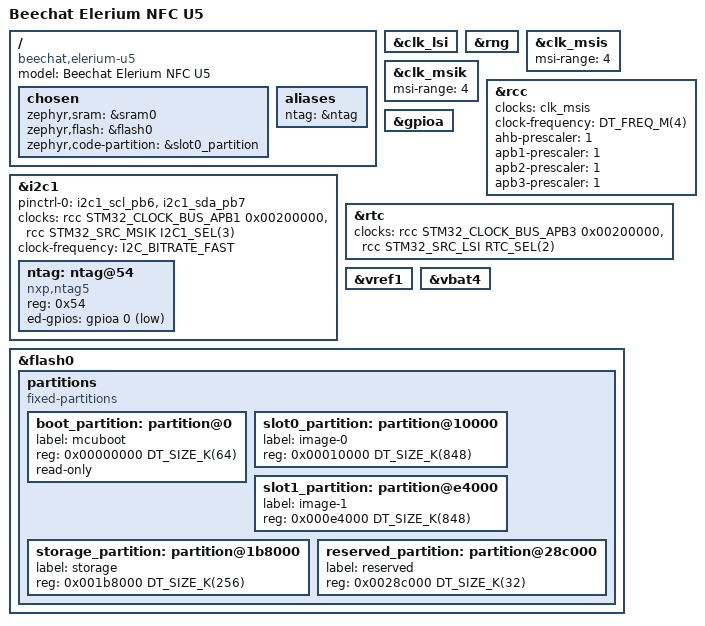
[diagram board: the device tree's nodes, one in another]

/dts-v1/;

#include <st/u5/stm32u585xi.dtsi>
#include <st/u5/stm32u585ciux-pinctrl.dtsi>
#include <zephyr/dt-bindings/clock/stm32u5_clock.h>

/ {
    model = "Beechat Elerium NFC U5";
    compatible = "beechat,elerium-u5", "st,stm32u585ci";

    chosen {
        zephyr,sram = &sram0;
        zephyr,flash = &flash0;
        zephyr,code-partition = &slot0_partition;
    };

    aliases {
        ntag = &ntag;
    };
};

&clk_lsi {
    status = "okay";
};

&rng {
    /* /delete-property/ clocks; */
    /* clocks = <&rcc STM32_CLOCK_BUS_AHB2 0x00040000>, <&rcc STM32_SRC_MSI RNG_SEL(1)>; */
    status = "okay";
};

&clk_msis {
    msi-range = <4>;
    status = "okay";
};

&clk_msik {
    msi-range = <4>;
    status = "okay";
};

&rcc {
    clocks = <&clk_msis>;
    clock-frequency = <DT_FREQ_M(4)>;
    ahb-prescaler = <1>;
    apb1-prescaler = <1>;
    apb2-prescaler = <1>;
    apb3-prescaler = <1>;
};

&i2c1 {
    pinctrl-0 = <&i2c1_scl_pb6 &i2c1_sda_pb7>;
    pinctrl-names = "default";

    clocks = <&rcc STM32_CLOCK_BUS_APB1 0x00200000>, <&rcc STM32_SRC_MSIK I2C1_SEL(3)>;

    clock-frequency = <I2C_BITRATE_FAST>;
    status = "okay";

    ntag: ntag@54 {
        reg = <0x54>;
        compatible = "nxp,ntag5";
        ed-gpios = <&gpioa 0 GPIO_ACTIVE_LOW>;
        status = "okay";
    };
};

&gpioa { 
    status = "okay";
};

&rtc {
    clocks = <&rcc STM32_CLOCK_BUS_APB3 0x00200000>, <&rcc STM32_SRC_LSI RTC_SEL(2)>;
    status = "okay";
};

&vref1 {
    status = "okay";
};

&vbat4 {
    status = "okay";
};

&flash0 {
    status = "okay";

    partitions {
        compatible = "fixed-partitions";
        #address-cells = <1>;
        #size-cells = <1>;

        boot_partition: partition@0 {
            label = "mcuboot";
            reg = <0x00000000 DT_SIZE_K(64)>;
            read-only;
        };

        slot0_partition: partition@10000 {
            label = "image-0";
            reg = <0x00010000 DT_SIZE_K(848)>;
        };

        slot1_partition: partition@e4000 {
            label = "image-1";
            reg = <0x000e4000 DT_SIZE_K(848)>;
        };

        storage_partition: partition@1b8000 {
            label = "storage";
            reg = <0x001b8000 DT_SIZE_K(256)>;
        };

        reserved_partition: partition@28c000 {
            label = "reserved";
            reg = <0x0028c000 DT_SIZE_K(32)>;
        };

    };
};
